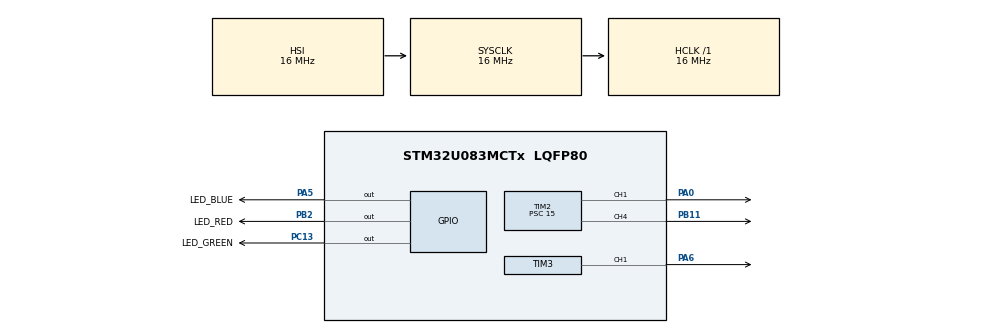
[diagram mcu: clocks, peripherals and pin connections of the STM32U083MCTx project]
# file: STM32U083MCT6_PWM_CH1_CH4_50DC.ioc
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Mcu.Family=STM32U0
Mcu.Name=STM32U083MCTx
Mcu.Package=LQFP80
NVIC.PriorityGroup=NVIC_PRIORITYGROUP_2
PA0.Signal=S_TIM2_CH1_ETR
PA10.GPIO_Label=COM2
PA10.Signal=LCD_COM2
PA11\ [PA9].GPIO_Label=USB_DM
PA11\ [PA9].Signal=USB_DM
PA12\ [PA10].GPIO_Label=USB_DP
PA12\ [PA10].Signal=USB_DP
PA13\ (SWDIO).GPIO_Label=SWDIO
PA13\ (SWDIO).Signal=DEBUG_JTMS-SWDIO
PA14\ (SWCLK).GPIO_Label=SWCLK
PA14\ (SWCLK).Signal=DEBUG_JTCK-SWCLK
PA2.GPIO_Label=VCP_TX
PA2.Signal=USART2_TX
PA3.GPIO_Label=VCP_RX
PA3.Signal=USART2_RX
PA5.GPIO_Label=LED_BLUE
PA5.Signal=GPIO_Output
PA6.Signal=S_TIM3_CH1
PA8.GPIO_Label=COM0
PA8.Signal=LCD_COM0
PA9.GPIO_Label=COM1
PA9.Signal=LCD_COM1
PB1.GPIO_Label=SEG2
PB1.Signal=LCD_SEG6
PB11.Signal=S_TIM2_CH4
PB12.GPIO_Label=SHIELD
PB12.Signal=TSC_G1_IO1
PB13.GPIO_Label=SHIELD_CS
PB13.Signal=TSC_G1_IO2
PB14.GPIO_Label=SEG7
PB14.Signal=LCD_SEG14
PB15.GPIO_Label=SEG8
PB15.Signal=LCD_SEG15
PB2.GPIO_Label=LED_RED
PB2.Signal=GPIO_Output
PB7.GPIO_Label=SDA
PB7.Signal=I2C1_SDA
PB8.GPIO_Label=SCL
PB8.Signal=I2C1_SCL
PB9.GPIO_Label=COM3
PB9.Signal=LCD_COM3
PC10.GPIO_Label=SEG16
PC10.Signal=LCD_SEG48
PC11.GPIO_Label=SEG23
PC11.Signal=LCD_SEG49
PC13.GPIO_Label=LED_GREEN
PC13.Signal=GPIO_Output
PC14-OSC32_IN.GPIO_Label=OSC32_IN
PC14-OSC32_IN.Signal=RCC_OSC32_IN
PC15-OSC32_OUT.GPIO_Label=OSC32_OUT
PC15-OSC32_OUT.Signal=RCC_OSC32_OUT
PC2.GPIO_Label=Joystick
PC2.Signal=ADC1_IN2
PC4.GPIO_Label=SEG0
PC4.Signal=LCD_SEG22
PC5.GPIO_Label=SEG1
PC5.Signal=LCD_SEG23
PC6.GPIO_Label=SEG13
PC6.Signal=LCD_SEG24
PC8.GPIO_Label=SEG14
PC8.Signal=LCD_SEG26
PC9.GPIO_Label=SEG15
PC9.Signal=LCD_SEG27
PD0.GPIO_Label=SEG17
PD0.Signal=LCD_SEG34
PD1.GPIO_Label=SEG18
PD1.Signal=LCD_SEG35
PD10.GPIO_Label=TEKY_CS
PD10.Signal=TSC_G6_IO1
PD11.GPIO_Label=TEKY
PD11.Signal=TSC_G6_IO2
PD12.GPIO_Label=SEG11
PD12.Signal=LCD_SEG32
PD13.GPIO_Label=SEG12
PD13.Signal=LCD_SEG33
PD3.GPIO_Label=SEG19
PD3.Signal=LCD_SEG36
PD4.GPIO_Label=SEG20
PD4.Signal=LCD_SEG37
PD5.GPIO_Label=SEG21
PD5.Signal=LCD_SEG38
PD6.GPIO_Label=SEG22
PD6.Signal=LCD_SEG39
PD8.GPIO_Label=SEG9
PD8.Signal=LCD_SEG28
PD9.GPIO_Label=SEG10
PD9.Signal=LCD_SEG29
PE7.GPIO_Label=SEG3
PE7.Signal=LCD_SEG45
PE8.GPIO_Label=SEG4
PE8.Signal=LCD_SEG46
PE9.GPIO_Label=SEG5
PE9.Signal=LCD_SEG47
PF0-OSC_IN.GPIO_Label=OSC_IN
PF0-OSC_IN.Signal=RCC_OSC_IN
PF1-OSC_OUT.GPIO_Label=OSC_OUT
PF1-OSC_OUT.Signal=RCC_OSC_OUT
ProjectManager.HeapSize=0x200
ProjectManager.StackSize=0x400
ProjectManager.TargetToolchain=STM32CubeIDE
RCC.AHBFreq_Value=16000000
RCC.CortexFreq_Value=16000000
RCC.HCLKFreq_Value=16000000
RCC.HSE_VALUE=4000000
RCC.HSI48_VALUE=48000000
RCC.HSI_VALUE=16000000
RCC.LSE_VALUE=32768
RCC.MSIClockRangeVal=RCC_MSIRANGE_11
RCC.MSI_VALUE=48000000
RCC.SYSCLKFreq_VALUE=16000000
RCC.USBFreq_Value=48000000
RCC.VCOOutputFreq_Value=64000000
SH.S_TIM2_CH1_ETR.0=TIM2_CH1,PWM Generation1 CH1
SH.S_TIM2_CH4.0=TIM2_CH4,PWM Generation4 CH4
SH.S_TIM3_CH1.0=TIM3_CH1,PWM Generation1 CH1
TIM2.AutoReloadPreload=TIM_AUTORELOAD_PRELOAD_ENABLE
TIM2.Channel-PWM\ Generation1\ CH1=TIM_CHANNEL_1
TIM2.Channel-PWM\ Generation4\ CH4=TIM_CHANNEL_4
TIM2.Period=999
TIM2.Prescaler=15
TIM2.Pulse-PWM\ Generation1\ CH1=500
TIM3.Channel-PWM\ Generation1\ CH1=TIM_CHANNEL_1
VP_PWR_VS_SECSignals.Mode=Security/Privilege
VP_TIM2_VS_ClockSourceINT.Mode=Internal
board=STM32U083C-DK

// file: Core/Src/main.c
/* USER CODE BEGIN Header */
/**
  ******************************************************************************
  * @file           : main.c
  * @brief          : Main program body
  ******************************************************************************
  * @attention
  *
  * Copyright (c) 2025 STMicroelectronics.
  * All rights reserved.
  *
  * This software is licensed under terms that can be found in the LICENSE file
  * in the root directory of this software component.
  * If no LICENSE file comes with this software, it is provided AS-IS.
  *
  ******************************************************************************
  */
/* USER CODE END Header */
#include "main.h"

TIM_HandleTypeDef htim2;
TIM_HandleTypeDef htim3;

void SystemClock_Config(void);
static void MX_GPIO_Init(void);
static void MX_TIM2_Init(void);
static void MX_TIM3_Init(void);

int main(void)
{

  /* MCU Configuration--------------------------------------------------------*/

  /* Reset of all peripherals, Initializes the Flash interface and the Systick. */
  HAL_Init();

  /* Configure the system clock */
  SystemClock_Config();

  /* Initialize all configured peripherals */
  MX_GPIO_Init();
  MX_TIM2_Init();
  MX_TIM3_Init();

  /* Infinite loop */
  /* USER CODE BEGIN WHILE */
  while (1)
  {
	HAL_TIM_PWM_Start(&htim2, TIM_CHANNEL_4);
	HAL_TIM_PWM_Start(&htim2, TIM_CHANNEL_1);
    /* USER CODE END WHILE */

  }
}

void SystemClock_Config(void)
{
  RCC_OscInitTypeDef RCC_OscInitStruct = {0};
  RCC_ClkInitTypeDef RCC_ClkInitStruct = {0};

  /** Configure the main internal regulator output voltage
  */
  HAL_PWREx_ControlVoltageScaling(PWR_REGULATOR_VOLTAGE_SCALE2);

  /** Initializes the RCC Oscillators according to the specified parameters
  * in the RCC_OscInitTypeDef structure.
  */
  RCC_OscInitStruct.OscillatorType = RCC_OSCILLATORTYPE_HSI;
  RCC_OscInitStruct.HSIState = RCC_HSI_ON;
  RCC_OscInitStruct.HSICalibrationValue = RCC_HSICALIBRATION_DEFAULT;
  RCC_OscInitStruct.PLL.PLLState = RCC_PLL_NONE;
  if (HAL_RCC_OscConfig(&RCC_OscInitStruct) != HAL_OK)
  {
    Error_Handler();
  }

  /** Initializes the CPU, AHB and APB buses clocks
  */
  RCC_ClkInitStruct.ClockType = RCC_CLOCKTYPE_HCLK|RCC_CLOCKTYPE_SYSCLK
                              |RCC_CLOCKTYPE_PCLK1;
  RCC_ClkInitStruct.SYSCLKSource = RCC_SYSCLKSOURCE_HSI;
  RCC_ClkInitStruct.AHBCLKDivider = RCC_SYSCLK_DIV1;
  RCC_ClkInitStruct.APB1CLKDivider = RCC_HCLK_DIV1;

  if (HAL_RCC_ClockConfig(&RCC_ClkInitStruct, FLASH_LATENCY_1) != HAL_OK)
  {
    Error_Handler();
  }
}

static void MX_TIM2_Init(void)
{

  TIM_ClockConfigTypeDef sClockSourceConfig = {0};
  TIM_MasterConfigTypeDef sMasterConfig = {0};
  TIM_OC_InitTypeDef sConfigOC = {0};

  htim2.Instance = TIM2;
  htim2.Init.Prescaler = 15;
  htim2.Init.CounterMode = TIM_COUNTERMODE_UP;
  htim2.Init.Period = 999;
  htim2.Init.ClockDivision = TIM_CLOCKDIVISION_DIV1;
  htim2.Init.AutoReloadPreload = TIM_AUTORELOAD_PRELOAD_ENABLE;
  if (HAL_TIM_Base_Init(&htim2) != HAL_OK)
  {
    Error_Handler();
  }
  sClockSourceConfig.ClockSource = TIM_CLOCKSOURCE_INTERNAL;
  if (HAL_TIM_ConfigClockSource(&htim2, &sClockSourceConfig) != HAL_OK)
  {
    Error_Handler();
  }
  if (HAL_TIM_PWM_Init(&htim2) != HAL_OK)
  {
    Error_Handler();
  }
  sMasterConfig.MasterOutputTrigger = TIM_TRGO_RESET;
  sMasterConfig.MasterSlaveMode = TIM_MASTERSLAVEMODE_DISABLE;
  if (HAL_TIMEx_MasterConfigSynchronization(&htim2, &sMasterConfig) != HAL_OK)
  {
    Error_Handler();
  }
  sConfigOC.OCMode = TIM_OCMODE_PWM1;
  sConfigOC.Pulse = 500;
  sConfigOC.OCPolarity = TIM_OCPOLARITY_HIGH;
  sConfigOC.OCFastMode = TIM_OCFAST_DISABLE;
  if (HAL_TIM_PWM_ConfigChannel(&htim2, &sConfigOC, TIM_CHANNEL_1) != HAL_OK)
  {
    Error_Handler();
  }
  sConfigOC.Pulse = 0;
  if (HAL_TIM_PWM_ConfigChannel(&htim2, &sConfigOC, TIM_CHANNEL_4) != HAL_OK)
  {
    Error_Handler();
  }
  HAL_TIM_MspPostInit(&htim2);

}

static void MX_TIM3_Init(void)
{

  TIM_MasterConfigTypeDef sMasterConfig = {0};
  TIM_OC_InitTypeDef sConfigOC = {0};

  htim3.Instance = TIM3;
  htim3.Init.Prescaler = 0;
  htim3.Init.CounterMode = TIM_COUNTERMODE_UP;
  htim3.Init.Period = 65535;
  htim3.Init.ClockDivision = TIM_CLOCKDIVISION_DIV1;
  htim3.Init.AutoReloadPreload = TIM_AUTORELOAD_PRELOAD_DISABLE;
  if (HAL_TIM_PWM_Init(&htim3) != HAL_OK)
  {
    Error_Handler();
  }
  sMasterConfig.MasterOutputTrigger = TIM_TRGO_RESET;
  sMasterConfig.MasterSlaveMode = TIM_MASTERSLAVEMODE_DISABLE;
  if (HAL_TIMEx_MasterConfigSynchronization(&htim3, &sMasterConfig) != HAL_OK)
  {
    Error_Handler();
  }
  sConfigOC.OCMode = TIM_OCMODE_PWM1;
  sConfigOC.Pulse = 0;
  sConfigOC.OCPolarity = TIM_OCPOLARITY_HIGH;
  sConfigOC.OCFastMode = TIM_OCFAST_DISABLE;
  if (HAL_TIM_PWM_ConfigChannel(&htim3, &sConfigOC, TIM_CHANNEL_1) != HAL_OK)
  {
    Error_Handler();
  }
  HAL_TIM_MspPostInit(&htim3);

}

static void MX_GPIO_Init(void)
{
  GPIO_InitTypeDef GPIO_InitStruct = {0};

  /* GPIO Ports Clock Enable */
  __HAL_RCC_GPIOC_CLK_ENABLE();
  __HAL_RCC_GPIOF_CLK_ENABLE();
  __HAL_RCC_GPIOA_CLK_ENABLE();
  __HAL_RCC_GPIOB_CLK_ENABLE();
  __HAL_RCC_GPIOE_CLK_ENABLE();
  __HAL_RCC_GPIOD_CLK_ENABLE();

  /*Configure GPIO pin Output Level */
  HAL_GPIO_WritePin(LED_GREEN_GPIO_Port, LED_GREEN_Pin, GPIO_PIN_RESET);

  /*Configure GPIO pin Output Level */
  HAL_GPIO_WritePin(LED_BLUE_GPIO_Port, LED_BLUE_Pin, GPIO_PIN_RESET);

  /*Configure GPIO pin Output Level */
  HAL_GPIO_WritePin(LED_RED_GPIO_Port, LED_RED_Pin, GPIO_PIN_RESET);

  /*Configure GPIO pin : LED_GREEN_Pin */
  GPIO_InitStruct.Pin = LED_GREEN_Pin;
  GPIO_InitStruct.Mode = GPIO_MODE_OUTPUT_PP;
  GPIO_InitStruct.Pull = GPIO_NOPULL;
  GPIO_InitStruct.Speed = GPIO_SPEED_FREQ_LOW;
  HAL_GPIO_Init(LED_GREEN_GPIO_Port, &GPIO_InitStruct);

  /*Configure GPIO pin : Joystick_Pin */
  GPIO_InitStruct.Pin = Joystick_Pin;
  GPIO_InitStruct.Mode = GPIO_MODE_ANALOG;
  GPIO_InitStruct.Pull = GPIO_NOPULL;
  HAL_GPIO_Init(Joystick_GPIO_Port, &GPIO_InitStruct);

  /*Configure GPIO pins : VCP_TX_Pin VCP_RX_Pin */
  GPIO_InitStruct.Pin = VCP_TX_Pin|VCP_RX_Pin;
  GPIO_InitStruct.Mode = GPIO_MODE_AF_PP;
  GPIO_InitStruct.Pull = GPIO_NOPULL;
  GPIO_InitStruct.Speed = GPIO_SPEED_FREQ_LOW;
  GPIO_InitStruct.Alternate = GPIO_AF7_USART2;
  HAL_GPIO_Init(GPIOA, &GPIO_InitStruct);

  /*Configure GPIO pin : LED_BLUE_Pin */
  GPIO_InitStruct.Pin = LED_BLUE_Pin;
  GPIO_InitStruct.Mode = GPIO_MODE_OUTPUT_PP;
  GPIO_InitStruct.Pull = GPIO_NOPULL;
  GPIO_InitStruct.Speed = GPIO_SPEED_FREQ_LOW;
  HAL_GPIO_Init(LED_BLUE_GPIO_Port, &GPIO_InitStruct);

  /*Configure GPIO pins : SEG0_Pin SEG1_Pin SEG13_Pin SEG14_Pin
                           SEG15_Pin SEG16_Pin SEG23_Pin */
  GPIO_InitStruct.Pin = SEG0_Pin|SEG1_Pin|SEG13_Pin|SEG14_Pin
                          |SEG15_Pin|SEG16_Pin|SEG23_Pin;
  GPIO_InitStruct.Mode = GPIO_MODE_AF_PP;
  GPIO_InitStruct.Pull = GPIO_NOPULL;
  GPIO_InitStruct.Speed = GPIO_SPEED_FREQ_LOW;
  GPIO_InitStruct.Alternate = GPIO_AF11_LCD;
  HAL_GPIO_Init(GPIOC, &GPIO_InitStruct);

  /*Configure GPIO pins : SEG2_Pin SEG7_Pin SEG8_Pin COM3_Pin */
  GPIO_InitStruct.Pin = SEG2_Pin|SEG7_Pin|SEG8_Pin|COM3_Pin;
  GPIO_InitStruct.Mode = GPIO_MODE_AF_PP;
  GPIO_InitStruct.Pull = GPIO_NOPULL;
  GPIO_InitStruct.Speed = GPIO_SPEED_FREQ_LOW;
  GPIO_InitStruct.Alternate = GPIO_AF11_LCD;
  HAL_GPIO_Init(GPIOB, &GPIO_InitStruct);

  /*Configure GPIO pin : LED_RED_Pin */
  GPIO_InitStruct.Pin = LED_RED_Pin;
  GPIO_InitStruct.Mode = GPIO_MODE_OUTPUT_PP;
  GPIO_InitStruct.Pull = GPIO_NOPULL;
  GPIO_InitStruct.Speed = GPIO_SPEED_FREQ_LOW;
  HAL_GPIO_Init(LED_RED_GPIO_Port, &GPIO_InitStruct);

  /*Configure GPIO pins : SEG3_Pin SEG4_Pin SEG5_Pin */
  GPIO_InitStruct.Pin = SEG3_Pin|SEG4_Pin|SEG5_Pin;
  GPIO_InitStruct.Mode = GPIO_MODE_AF_PP;
  GPIO_InitStruct.Pull = GPIO_NOPULL;
  GPIO_InitStruct.Speed = GPIO_SPEED_FREQ_LOW;
  GPIO_InitStruct.Alternate = GPIO_AF11_LCD;
  HAL_GPIO_Init(GPIOE, &GPIO_InitStruct);

  /*Configure GPIO pins : SHIELD_Pin SHIELD_CS_Pin */
  GPIO_InitStruct.Pin = SHIELD_Pin|SHIELD_CS_Pin;
  GPIO_InitStruct.Mode = GPIO_MODE_AF_PP;
  GPIO_InitStruct.Pull = GPIO_NOPULL;
  GPIO_InitStruct.Speed = GPIO_SPEED_FREQ_LOW;
  GPIO_InitStruct.Alternate = GPIO_AF9_TSC;
  HAL_GPIO_Init(GPIOB, &GPIO_InitStruct);

  /*Configure GPIO pins : SEG9_Pin SEG10_Pin SEG11_Pin SEG12_Pin
                           SEG17_Pin SEG18_Pin SEG19_Pin SEG20_Pin
                           SEG21_Pin SEG22_Pin */
  GPIO_InitStruct.Pin = SEG9_Pin|SEG10_Pin|SEG11_Pin|SEG12_Pin
                          |SEG17_Pin|SEG18_Pin|SEG19_Pin|SEG20_Pin
                          |SEG21_Pin|SEG22_Pin;
  GPIO_InitStruct.Mode = GPIO_MODE_AF_PP;
  GPIO_InitStruct.Pull = GPIO_NOPULL;
  GPIO_InitStruct.Speed = GPIO_SPEED_FREQ_LOW;
  GPIO_InitStruct.Alternate = GPIO_AF11_LCD;
  HAL_GPIO_Init(GPIOD, &GPIO_InitStruct);

  /*Configure GPIO pins : TEKY_CS_Pin TEKY_Pin */
  GPIO_InitStruct.Pin = TEKY_CS_Pin|TEKY_Pin;
  GPIO_InitStruct.Mode = GPIO_MODE_AF_PP;
  GPIO_InitStruct.Pull = GPIO_NOPULL;
  GPIO_InitStruct.Speed = GPIO_SPEED_FREQ_LOW;
  GPIO_InitStruct.Alternate = GPIO_AF9_TSC;
  HAL_GPIO_Init(GPIOD, &GPIO_InitStruct);

  /*Configure GPIO pins : COM0_Pin COM1_Pin COM2_Pin */
  GPIO_InitStruct.Pin = COM0_Pin|COM1_Pin|COM2_Pin;
  GPIO_InitStruct.Mode = GPIO_MODE_AF_PP;
  GPIO_InitStruct.Pull = GPIO_NOPULL;
  GPIO_InitStruct.Speed = GPIO_SPEED_FREQ_LOW;
  GPIO_InitStruct.Alternate = GPIO_AF11_LCD;
  HAL_GPIO_Init(GPIOA, &GPIO_InitStruct);

  /*Configure GPIO pins : USB_DM_Pin USB_DP_Pin */
  GPIO_InitStruct.Pin = USB_DM_Pin|USB_DP_Pin;
  GPIO_InitStruct.Mode = GPIO_MODE_AF_PP;
  GPIO_InitStruct.Pull = GPIO_NOPULL;
  GPIO_InitStruct.Speed = GPIO_SPEED_FREQ_LOW;
  HAL_GPIO_Init(GPIOA, &GPIO_InitStruct);

  /*Configure GPIO pins : SDA_Pin SCL_Pin */
  GPIO_InitStruct.Pin = SDA_Pin|SCL_Pin;
  GPIO_InitStruct.Mode = GPIO_MODE_AF_OD;
  GPIO_InitStruct.Pull = GPIO_NOPULL;
  GPIO_InitStruct.Speed = GPIO_SPEED_FREQ_LOW;
  GPIO_InitStruct.Alternate = GPIO_AF4_I2C1;
  HAL_GPIO_Init(GPIOB, &GPIO_InitStruct);

}

void Error_Handler(void)
{
  __disable_irq();
  while (1)
  {
  }
}
